# ESP32 register map
Vendor: ESPRESSIF SYSTEMS (SHANGHAI) CO., LTD.; Series: ESP32 Series; File version: 17
CPU: Xtensa LX6 r0p0, little endian, no MPU, FPU, 0 interrupt priority bits
Address unit: 32 bits
Registers are 32-bit, read-write, reset 0x0 unless marked. A register's access mark holds for its fields unless they carry their own. Offsets are from the block's base; [hi:lo] are bit positions.

## UART0 — UART (Universal Asynchronous Receiver-Transmitter) Controller 0
Base 0x3FF40000
Same registers: UART1 0x3FF50000, UART2 0x3FF6E000
0x00 FIFO
  [7:0] RXFIFO_RD_BYTE — This register stores one byte data read by rx fifo.
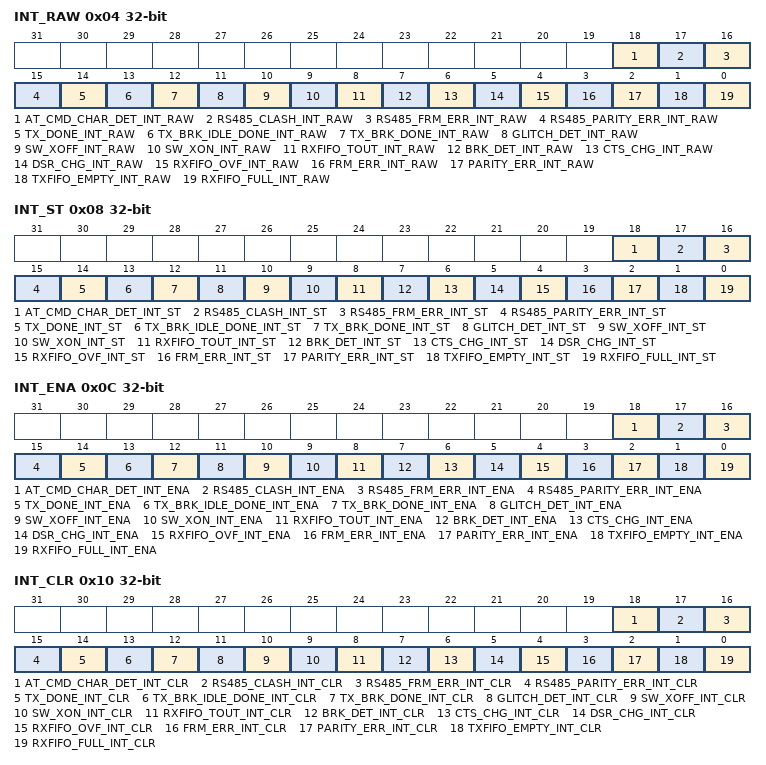
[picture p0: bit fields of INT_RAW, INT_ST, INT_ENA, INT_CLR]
0x04 INT_RAW ro
  [18] AT_CMD_CHAR_DET_INT_RAW — This interrupt raw bit turns to high level when receiver detects the configured at_cmd chars.
  [17] RS485_CLASH_INT_RAW — This interrupt raw bit turns to high level when rs485 detects the clash between transmitter and receiver.
  [16] RS485_FRM_ERR_INT_RAW — This interrupt raw bit turns to high level when rs485 detects the data frame error.
  [15] RS485_PARITY_ERR_INT_RAW — This interrupt raw bit turns to high level when rs485 detects the parity error.
  [14] TX_DONE_INT_RAW — This interrupt raw bit turns to high level when transmitter has send all the data in fifo.
  [13] TX_BRK_IDLE_DONE_INT_RAW — This interrupt raw bit turns to high level when transmitter has kept the shortest duration after the last data has been send.
  [12] TX_BRK_DONE_INT_RAW — This interrupt raw bit turns to high level when transmitter completes sendding 0 after all the datas in transmitter's fifo are send.
  [11] GLITCH_DET_INT_RAW — This interrupt raw bit turns to high level when receiver detects the start bit.
  [10] SW_XOFF_INT_RAW — This interrupt raw bit turns to high level when receiver receives xon char with uart_sw_flow_con_en is set to 1.
  [9] SW_XON_INT_RAW — This interrupt raw bit turns to high level when receiver receives xoff char with uart_sw_flow_con_en is set to 1.
  [8] RXFIFO_TOUT_INT_RAW — This interrupt raw bit turns to high level when receiver takes more time than rx_tout_thrhd to receive a byte.
  [7] BRK_DET_INT_RAW — This interrupt raw bit turns to high level when receiver detects the 0 after the stop bit.
  [6] CTS_CHG_INT_RAW — This interrupt raw bit turns to high level when receiver detects the edge change of ctsn signal.
  [5] DSR_CHG_INT_RAW — This interrupt raw bit turns to high level when receiver detects the edge change of dsrn signal.
  [4] RXFIFO_OVF_INT_RAW — This interrupt raw bit turns to high level when receiver receives more data than the fifo can store.
  [3] FRM_ERR_INT_RAW — This interrupt raw bit turns to high level when receiver detects data's frame error .
  [2] PARITY_ERR_INT_RAW — This interrupt raw bit turns to high level when receiver detects the parity error of data.
  [1] TXFIFO_EMPTY_INT_RAW — This interrupt raw bit turns to high level when the amount of data in transmitter's fifo is less than ((tx_mem_cnttxfifo_cnt) .
  [0] RXFIFO_FULL_INT_RAW — This interrupt raw bit turns to high level when receiver receives more data than (rx_flow_thrhd_h3 rx_flow_thrhd).
0x08 INT_ST ro
  [18] AT_CMD_CHAR_DET_INT_ST — This is the status bit for at_cmd_det_int_raw when at_cmd_char_det_int_ena is set to 1.
  [17] RS485_CLASH_INT_ST — This is the status bit for rs485_clash_int_raw when rs485_clash_int_ena is set to 1.
  [16] RS485_FRM_ERR_INT_ST — This is the status bit for rs485_fm_err_int_raw when rs485_fm_err_int_ena is set to 1.
  [15] RS485_PARITY_ERR_INT_ST — This is the status bit for rs485_parity_err_int_raw when rs485_parity_int_ena is set to 1.
  [14] TX_DONE_INT_ST — This is the status bit for tx_done_int_raw when tx_done_int_ena is set to 1.
  [13] TX_BRK_IDLE_DONE_INT_ST — This is the stauts bit for tx_brk_idle_done_int_raw when tx_brk_idle_done_int_ena is set to 1.
  [12] TX_BRK_DONE_INT_ST — This is the status bit for tx_brk_done_int_raw when tx_brk_done_int_ena is set to 1.
  [11] GLITCH_DET_INT_ST — This is the status bit for glitch_det_int_raw when glitch_det_int_ena is set to 1.
  [10] SW_XOFF_INT_ST — This is the status bit for sw_xoff_int_raw when sw_xoff_int_ena is set to 1.
  [9] SW_XON_INT_ST — This is the status bit for sw_xon_int_raw when sw_xon_int_ena is set to 1.
  [8] RXFIFO_TOUT_INT_ST — This is the status bit for rxfifo_tout_int_raw when rxfifo_tout_int_ena is set to 1.
  [7] BRK_DET_INT_ST — This is the status bit for brk_det_int_raw when brk_det_int_ena is set to 1.
  [6] CTS_CHG_INT_ST — This is the status bit for cts_chg_int_raw when cts_chg_int_ena is set to 1.
  [5] DSR_CHG_INT_ST — This is the status bit for dsr_chg_int_raw when dsr_chg_int_ena is set to 1.
  [4] RXFIFO_OVF_INT_ST — This is the status bit for rxfifo_ovf_int_raw when rxfifo_ovf_int_ena is set to 1.
  [3] FRM_ERR_INT_ST — This is the status bit for frm_err_int_raw when fm_err_int_ena is set to 1.
  [2] PARITY_ERR_INT_ST — This is the status bit for parity_err_int_raw when parity_err_int_ena is set to 1.
  [1] TXFIFO_EMPTY_INT_ST — This is the status bit for txfifo_empty_int_raw when txfifo_empty_int_ena is set to 1.
  [0] RXFIFO_FULL_INT_ST — This is the status bit for rxfifo_full_int_raw when rxfifo_full_int_ena is set to 1.
0x0C INT_ENA
  [18] AT_CMD_CHAR_DET_INT_ENA — This is the enable bit for at_cmd_char_det_int_st register.
  [17] RS485_CLASH_INT_ENA — This is the enable bit for rs485_clash_int_st register.
  [16] RS485_FRM_ERR_INT_ENA — This is the enable bit for rs485_parity_err_int_st register.
  [15] RS485_PARITY_ERR_INT_ENA — This is the enable bit for rs485_parity_err_int_st register.
  [14] TX_DONE_INT_ENA — This is the enable bit for tx_done_int_st register.
  [13] TX_BRK_IDLE_DONE_INT_ENA — This is the enable bit for tx_brk_idle_done_int_st register.
  [12] TX_BRK_DONE_INT_ENA — This is the enable bit for tx_brk_done_int_st register.
  [11] GLITCH_DET_INT_ENA — This is the enable bit for glitch_det_int_st register.
  [10] SW_XOFF_INT_ENA — This is the enable bit for sw_xoff_int_st register.
  [9] SW_XON_INT_ENA — This is the enable bit for sw_xon_int_st register.
  [8] RXFIFO_TOUT_INT_ENA — This is the enable bit for rxfifo_tout_int_st register.
  [7] BRK_DET_INT_ENA — This is the enable bit for brk_det_int_st register.
  [6] CTS_CHG_INT_ENA — This is the enable bit for cts_chg_int_st register.
  [5] DSR_CHG_INT_ENA — This is the enable bit for dsr_chg_int_st register.
  [4] RXFIFO_OVF_INT_ENA — This is the enable bit for rxfifo_ovf_int_st register.
  [3] FRM_ERR_INT_ENA — This is the enable bit for frm_err_int_st register.
  [2] PARITY_ERR_INT_ENA — This is the enable bit for parity_err_int_st register.
  [1] TXFIFO_EMPTY_INT_ENA — This is the enable bit for rxfifo_full_int_st register.
  [0] RXFIFO_FULL_INT_ENA — This is the enable bit for rxfifo_full_int_st register.
0x10 INT_CLR wo
  [18] AT_CMD_CHAR_DET_INT_CLR — Set this bit to clear the at_cmd_char_det_int_raw interrupt.
  [17] RS485_CLASH_INT_CLR — Set this bit to clear the rs485_clash_int_raw interrupt.
  [16] RS485_FRM_ERR_INT_CLR — Set this bit to clear the rs485_frm_err_int_raw interrupt.
  [15] RS485_PARITY_ERR_INT_CLR — Set this bit to clear the rs485_parity_err_int_raw interrupt.
  [14] TX_DONE_INT_CLR — Set this bit to clear the tx_done_int_raw interrupt.
  [13] TX_BRK_IDLE_DONE_INT_CLR — Set this bit to clear the tx_brk_idle_done_int_raw interrupt.
  [12] TX_BRK_DONE_INT_CLR — Set this bit to clear the tx_brk_done_int_raw interrupt..
  [11] GLITCH_DET_INT_CLR — Set this bit to clear the glitch_det_int_raw interrupt.
  [10] SW_XOFF_INT_CLR — Set this bit to clear the sw_xon_int_raw interrupt.
  [9] SW_XON_INT_CLR — Set this bit to clear the sw_xon_int_raw interrupt.
  [8] RXFIFO_TOUT_INT_CLR — Set this bit to clear the rxfifo_tout_int_raw interrupt.
  [7] BRK_DET_INT_CLR — Set this bit to clear the brk_det_int_raw interrupt.
  [6] CTS_CHG_INT_CLR — Set this bit to clear the cts_chg_int_raw interrupt.
  [5] DSR_CHG_INT_CLR — Set this bit to clear the dsr_chg_int_raw interrupt.
  [4] RXFIFO_OVF_INT_CLR — Set this bit to clear rxfifo_ovf_int_raw interrupt.
  [3] FRM_ERR_INT_CLR — Set this bit to clear frm_err_int_raw interrupt.
  [2] PARITY_ERR_INT_CLR — Set this bit to clear parity_err_int_raw interrupt.
  [1] TXFIFO_EMPTY_INT_CLR — Set this bit to clear txfifo_empty_int_raw interrupt.
  [0] RXFIFO_FULL_INT_CLR — Set this bit to clear the rxfifo_full_int_raw interrupt.
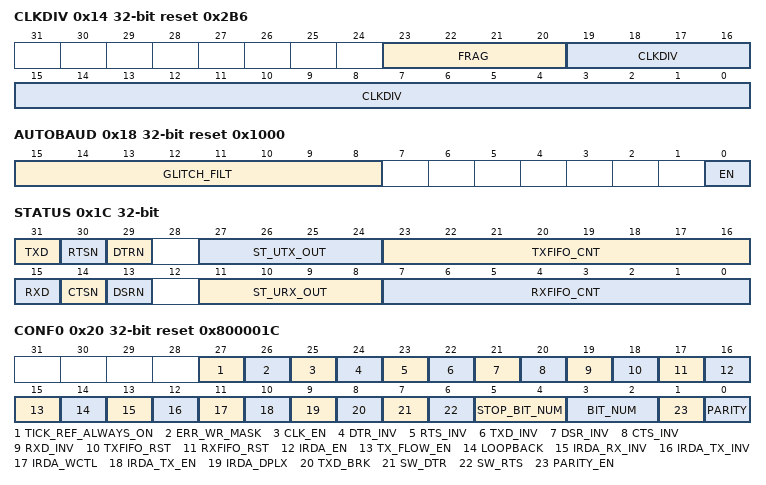
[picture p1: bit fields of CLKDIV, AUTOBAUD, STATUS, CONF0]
0x14 CLKDIV reset 0x2B6
  [23:20] FRAG — The register value is the decimal part of the frequency divider's factor.
  [19:0] CLKDIV — The register value is the integer part of the frequency divider's factor.
0x18 AUTOBAUD reset 0x1000
  [15:8] GLITCH_FILT — when input pulse width is lower then this value igore this pulse.this register is used in autobaud detect process.
  [0] EN — This is the enable bit for detecting baudrate.
0x1C STATUS ro
  [31] TXD — This register represent the level value of the internal uart rxd signal.
  [30] RTSN — This register represent the level value of the internal uart cts signal.
  [29] DTRN — The register represent the level value of the internal uart dsr signal.
  [27:24] ST_UTX_OUT — This register stores the value of transmitter's finite state machine. 0:TX_IDLE 1:TX_STRT 2:TX_DAT0 3:TX_DAT1 4:TX_DAT2 5:TX_DAT3 6:TX_DAT4 7:TX_DAT5 8:TX_DAT6 9:TX_DAT7 10:TX_PRTY 11:TX_STP1 12:TX_STP2 13:TX_DL0 14:TX_DL1
  [23:16] TXFIFO_CNT — (tx_mem_cnt txfifo_cnt) stores the byte num of valid datas in transmitter's fifo.tx_mem_cnt stores the 3 most significant bits txfifo_cnt stores the 8 least significant bits.
  [15] RXD — This register stores the level value of the internal uart rxd signal.
  [14] CTSN — This register stores the level value of the internal uart cts signal.
  [13] DSRN — This register stores the level value of the internal uart dsr signal.
  [11:8] ST_URX_OUT — This register stores the value of receiver's finite state machine. 0:RX_IDLE 1:RX_STRT 2:RX_DAT0 3:RX_DAT1 4:RX_DAT2 5:RX_DAT3 6:RX_DAT4 7:RX_DAT5 8:RX_DAT6 9:RX_DAT7 10:RX_PRTY 11:RX_STP1 12:RX_STP2 13:RX_DL1
  [7:0] RXFIFO_CNT — (rx_mem_cnt rxfifo_cnt) stores the byte num of valid datas in receiver's fifo. rx_mem_cnt register stores the 3 most significant bits rxfifo_cnt stores the 8 least significant bits.
0x20 CONF0 reset 0x800001C
  [27] TICK_REF_ALWAYS_ON — This register is used to select the clock.1.apb clock 0:ref_tick
  [26] ERR_WR_MASK — 1.receiver stops storing data int fifo when data is wrong. 0.receiver stores the data even if the received data is wrong.
  [25] CLK_EN — 1.force clock on for registers.support clock only when write registers
  [24] DTR_INV — Set this bit to inverse the level value of uart dtr signal.
  [23] RTS_INV — Set this bit to inverse the level value of uart rts signal.
  [22] TXD_INV — Set this bit to inverse the level value of uart txd signal.
  [21] DSR_INV — Set this bit to inverse the level value of uart dsr signal.
  [20] CTS_INV — Set this bit to inverse the level value of uart cts signal.
  [19] RXD_INV — Set this bit to inverse the level value of uart rxd signal.
  [18] TXFIFO_RST — Set this bit to reset uart transmitter's fifo.
  [17] RXFIFO_RST — Set this bit to reset uart receiver's fifo.
  [16] IRDA_EN — Set this bit to enable irda protocol.
  [15] TX_FLOW_EN — Set this bit to enable transmitter's flow control function.
  [14] LOOPBACK — Set this bit to enable uart loopback test mode.
  [13] IRDA_RX_INV — Set this bit to inverse the level value of irda receiver's level.
  [12] IRDA_TX_INV — Set this bit to inverse the level value of irda transmitter's level.
  [11] IRDA_WCTL — 1.the irda transmitter's 11th bit is the same to the 10th bit. 0.set irda transmitter's 11th bit to 0.
  [10] IRDA_TX_EN — This is the start enable bit for irda transmitter.
  [9] IRDA_DPLX — Set this bit to enable irda loopback mode.
  [8] TXD_BRK — Set this bit to enbale transmitter to send 0 when the process of sending data is done.
  [7] SW_DTR — This register is used to configure the software dtr signal which is used in software flow control..
  [6] SW_RTS — This register is used to configure the software rts signal which is used in software flow control.
  [5:4] STOP_BIT_NUM — This register is used to set the length of stop bit. 1:1bit 2:1.5bits 3:2bits
  [3:2] BIT_NUM — This registe is used to set the length of data: 0:5bits 1:6bits 2:7bits 3:8bits
  [1] PARITY_EN — Set this bit to enable uart parity check.
  [0] PARITY — This register is used to configure the parity check mode. 0:even 1:odd
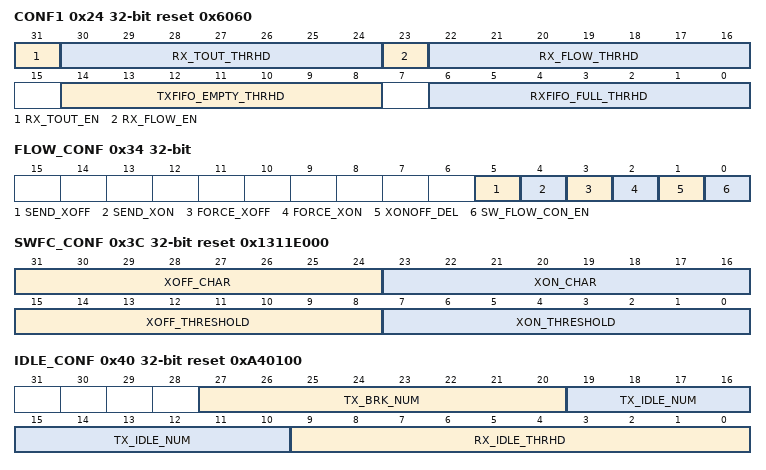
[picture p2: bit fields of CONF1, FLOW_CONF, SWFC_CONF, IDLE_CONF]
0x24 CONF1 reset 0x6060
  [31] RX_TOUT_EN — This is the enble bit for uart receiver's timeout function.
  [30:24] RX_TOUT_THRHD — This register is used to configure the timeout value for uart receiver receiving a byte.
  [23] RX_FLOW_EN — This is the flow enable bit for uart receiver. 1:choose software flow control with configuring sw_rts signal
  [22:16] RX_FLOW_THRHD — when receiver receives more data than its threshold value. receiver produce signal to tell the transmitter stop transferring data. the threshold value is (rx_flow_thrhd_h3 rx_flow_thrhd).
  [14:8] TXFIFO_EMPTY_THRHD — when the data amount in transmitter fifo is less than its threshold value. it will produce txfifo_empty_int_raw interrupt. the threshold value is (tx_mem_empty_thrhd txfifo_empty_thrhd)
  [6:0] RXFIFO_FULL_THRHD — When receiver receives more data than its threshold value.receiver will produce rxfifo_full_int_raw interrupt.the threshold value is (rx_flow_thrhd_h3 rxfifo_full_thrhd).
0x28 LOWPULSE ro reset 0xFFFFF
  [19:0] MIN_CNT — This register stores the value of the minimum duration time for the low level pulse. it is used in baudrate-detect process.
0x2C HIGHPULSE ro reset 0xFFFFF
  [19:0] MIN_CNT — This register stores the value of the maxinum duration time for the high level pulse. it is used in baudrate-detect process.
0x30 RXD_CNT ro
  [9:0] RXD_EDGE_CNT — This register stores the count of rxd edge change. it is used in baudrate-detect process.
0x34 FLOW_CONF
  [5] SEND_XOFF — Set this bit to send xoff char. it is cleared by hardware automatically.
  [4] SEND_XON — Set this bit to send xon char. it is cleared by hardware automatically.
  [3] FORCE_XOFF — Set this bit to set ctsn to enable the transmitter to go on sending data.
  [2] FORCE_XON — Set this bit to clear ctsn to stop the transmitter from sending data.
  [1] XONOFF_DEL — Set this bit to remove flow control char from the received data.
  [0] SW_FLOW_CON_EN — Set this bit to enable software flow control. it is used with register sw_xon or sw_xoff .
0x38 SLEEP_CONF reset 0xF0
  [9:0] ACTIVE_THRESHOLD — When the input rxd edge changes more than this register value. the uart is active from light sleeping mode.
0x3C SWFC_CONF reset 0x1311E000
  [31:24] XOFF_CHAR — This register stores the xoff flow control char.
  [23:16] XON_CHAR — This register stores the xon flow control char.
  [15:8] XOFF_THRESHOLD — When the data amount in receiver's fifo is less than this register value. it will send a xon char with uart_sw_flow_con_en set to 1.
  [7:0] XON_THRESHOLD — when the data amount in receiver's fifo is more than this register value. it will send a xoff char with uart_sw_flow_con_en set to 1.
0x40 IDLE_CONF reset 0xA40100
  [27:20] TX_BRK_NUM — This register is used to configure the num of 0 send after the process of sending data is done. it is active when txd_brk is set to 1.
  [19:10] TX_IDLE_NUM — This register is used to configure the duration time between transfers.
  [9:0] RX_IDLE_THRHD — when receiver takes more time than this register value to receive a byte data. it will produce frame end signal for uhci to stop receiving data.
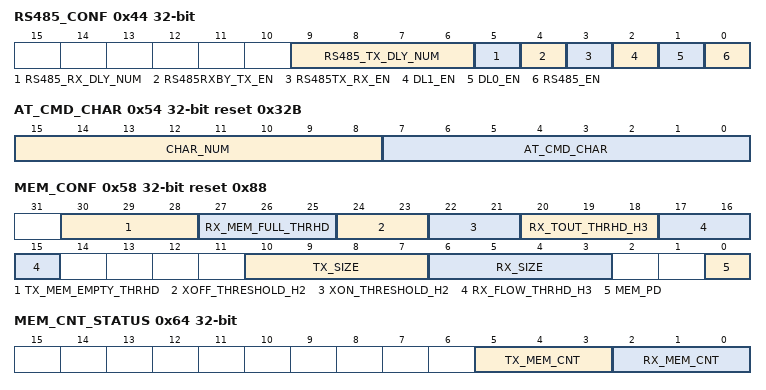
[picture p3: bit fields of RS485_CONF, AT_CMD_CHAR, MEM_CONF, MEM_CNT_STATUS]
0x44 RS485_CONF
  [9:6] RS485_TX_DLY_NUM — This register is used to delay the transmitter's internal data signal.
  [5] RS485_RX_DLY_NUM — This register is used to delay the receiver's internal data signal.
  [4] RS485RXBY_TX_EN — 1: enable rs485's transmitter to send data when rs485's receiver is busy. 0:rs485's transmitter should not send data when its receiver is busy.
  [3] RS485TX_RX_EN — Set this bit to enable loopback transmitter's output data signal to receiver's input data signal.
  [2] DL1_EN — Set this bit to delay the stop bit by 1 bit.
  [1] DL0_EN — Set this bit to delay the stop bit by 1 bit.
  [0] RS485_EN — Set this bit to choose rs485 mode.
0x48 AT_CMD_PRECNT reset 0x186A00
  [23:0] PRE_IDLE_NUM — This register is used to configure the idle duration time before the first at_cmd is received by receiver. when the the duration is less than this register value it will not take the next data received as at_cmd char.
0x4C AT_CMD_POSTCNT reset 0x186A00
  [23:0] POST_IDLE_NUM — This register is used to configure the duration time between the last at_cmd and the next data. when the duration is less than this register value it will not take the previous data as at_cmd char.
0x50 AT_CMD_GAPTOUT reset 0x1E00
  [23:0] RX_GAP_TOUT — This register is used to configure the duration time between the at_cmd chars. when the duration time is less than this register value it will not take the datas as continous at_cmd chars.
0x54 AT_CMD_CHAR reset 0x32B
  [15:8] CHAR_NUM — This register is used to configure the num of continous at_cmd chars received by receiver.
  [7:0] AT_CMD_CHAR — This register is used to configure the content of at_cmd char.
0x58 MEM_CONF reset 0x88
  [30:28] TX_MEM_EMPTY_THRHD — Refer to txfifo_empty_thrhd's description.
  [27:25] RX_MEM_FULL_THRHD — Refer to the rxfifo_full_thrhd's description.
  [24:23] XOFF_THRESHOLD_H2 — Refer to the uart_xoff_threshold's description.
  [22:21] XON_THRESHOLD_H2 — Refer to the uart_xon_threshold's description.
  [20:18] RX_TOUT_THRHD_H3 — Refer to the rx_tout_thrhd's description.
  [17:15] RX_FLOW_THRHD_H3 — Refer to the rx_flow_thrhd's description.
  [10:7] TX_SIZE — This register is used to configure the amount of mem allocated to transmitter's fifo.the default byte num is 128.
  [6:3] RX_SIZE — This register is used to configure the amount of mem allocated to receiver's fifo. the default byte num is 128.
  [0] MEM_PD — Set this bit to power down mem.when reg_mem_pd registers in the 3 uarts are all set to 1 mem will enter low power mode.
0x5C MEM_TX_STATUS ro
  [23:0] MEM_TX_STATUS
0x60 MEM_RX_STATUS ro
  [23:13] MEM_RX_WR_ADDR — This register stores the rx mem write address
  [12:2] MEM_RX_RD_ADDR — This register stores the rx mem read address
  [23:0] MEM_RX_STATUS — This register stores the current uart rx mem read address and rx mem write address
0x64 MEM_CNT_STATUS ro
  [5:3] TX_MEM_CNT — Refer to the txfifo_cnt's description.
  [2:0] RX_MEM_CNT — Refer to the rxfifo_cnt's description.
0x68 POSPULSE ro reset 0xFFFFF
  [19:0] POSEDGE_MIN_CNT — This register stores the count of rxd posedge edge. it is used in boudrate-detect process.
0x6C NEGPULSE ro reset 0xFFFFF
  [19:0] NEGEDGE_MIN_CNT — This register stores the count of rxd negedge edge. it is used in boudrate-detect process.
0x78 DATE reset 0x15122500
0x7C ID reset 0x500
